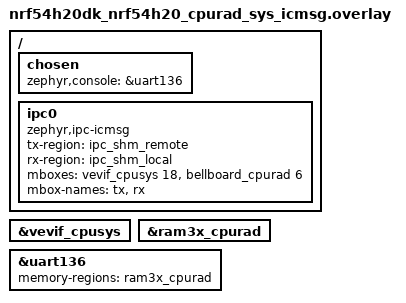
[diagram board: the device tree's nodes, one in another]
/*
 * Copyright (c) 2022 Nordic Semiconductor ASA
 *
 * SPDX-License-Identifier: Apache-2.0
 */

#include <common/nordic_nrf_next/nrfx_ram3x_dma.dtsi>
#include "shared/nrf54_ipc_shm_ram2.dtsi"

/ {
	chosen {
		zephyr,console = &uart136;
	};

	ipc0: ipc0 {
		compatible = "zephyr,ipc-icmsg";
		tx-region = <&ipc_shm_remote>;
		rx-region = <&ipc_shm_local>;
		mboxes = <&vevif_cpusys 18>,
			 <&bellboard_cpurad 6>;
		mbox-names = "tx", "rx";
		status = "okay";
	};
};

&vevif_cpusys {
	status = "okay";
};

/* ram3x_cpurad buffer is used by Net core UART driver. */
&ram3x_cpurad {
	status = "okay";
};

&uart136 {
	status = "okay";
	memory-regions = <&ram3x_cpurad>;
};
